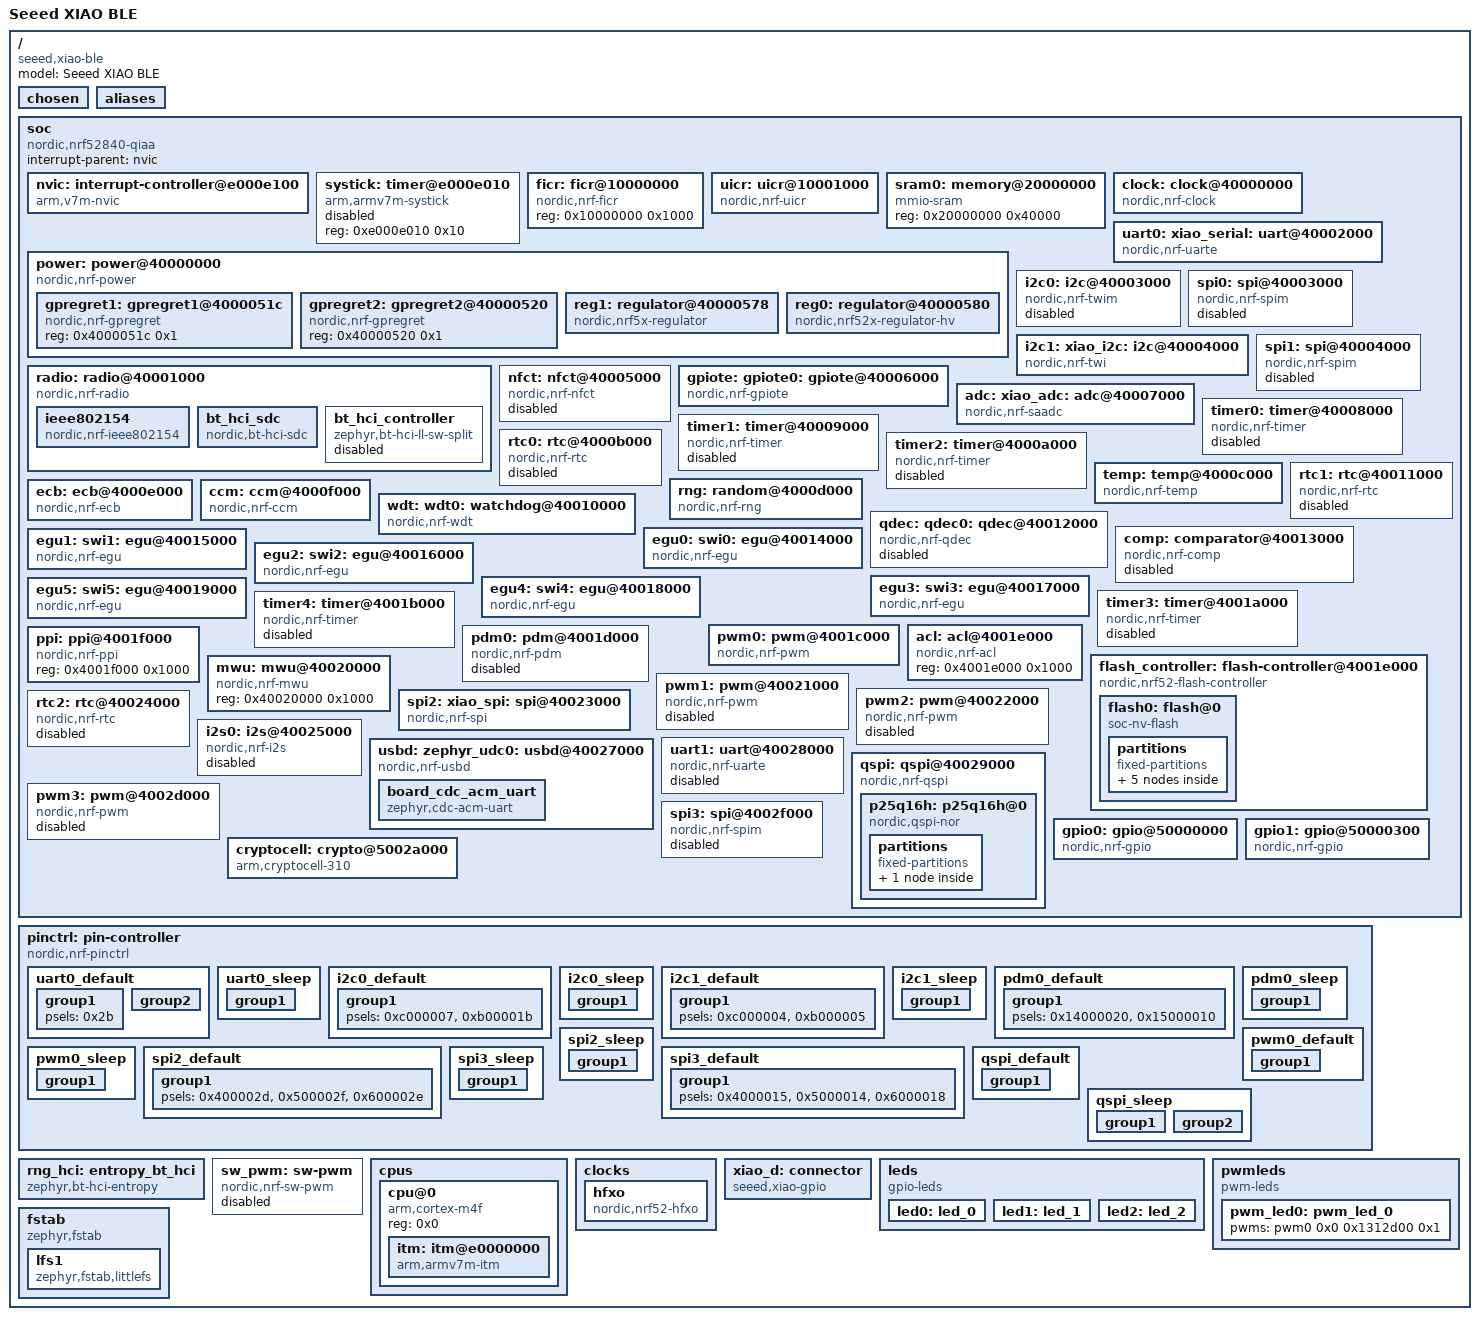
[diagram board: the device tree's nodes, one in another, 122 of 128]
/dts-v1/;

/* node '/' defined in zephyr\dts\common\skeleton.dtsi:9 */
/ {
	#address-cells = < 0x1 >;      /* in zephyr\dts\common\skeleton.dtsi:10 */
	#size-cells = < 0x1 >;         /* in zephyr\dts\common\skeleton.dtsi:11 */
	model = "Seeed XIAO BLE";      /* in zephyr\boards\seeed\xiao_ble\xiao_ble.dts:11 */
	compatible = "seeed,xiao-ble"; /* in zephyr\boards\seeed\xiao_ble\xiao_ble.dts:12 */

	/* node '/chosen' defined in zephyr\dts\common\skeleton.dtsi:12 */
	chosen {
		zephyr,bt-hci = &bt_hci_sdc;                 /* in zephyr\dts\arm\nordic\nrf52840.dtsi:10 */
		zephyr,entropy = &cryptocell;                /* in zephyr\dts\arm\nordic\nrf52840.dtsi:11 */
		zephyr,flash-controller = &flash_controller; /* in zephyr\dts\arm\nordic\nrf52840.dtsi:12 */
		zephyr,sram = &sram0;                        /* in zephyr\dts\vendor\nordic\nrf52840_partition_uf2_sdv7.dtsi:10 */
		zephyr,flash = &flash0;                      /* in zephyr\dts\vendor\nordic\nrf52840_partition_uf2_sdv7.dtsi:11 */
		zephyr,code-partition = &code_partition;     /* in zephyr\dts\vendor\nordic\nrf52840_partition_uf2_sdv7.dtsi:12 */
		zephyr,ieee802154 = &ieee802154;             /* in zephyr\boards\seeed\xiao_ble\xiao_ble_common.dtsi:15 */
		zephyr,console = &board_cdc_acm_uart;        /* in zephyr\boards\common\usb\cdc_acm_serial.dtsi:9 */
		zephyr,shell-uart = &board_cdc_acm_uart;     /* in zephyr\boards\common\usb\cdc_acm_serial.dtsi:10 */
		zephyr,uart-mcumgr = &board_cdc_acm_uart;    /* in zephyr\boards\common\usb\cdc_acm_serial.dtsi:11 */
		zephyr,bt-mon-uart = &board_cdc_acm_uart;    /* in zephyr\boards\common\usb\cdc_acm_serial.dtsi:12 */
		zephyr,bt-c2h-uart = &board_cdc_acm_uart;    /* in zephyr\boards\common\usb\cdc_acm_serial.dtsi:13 */
		nordic,pm-ext-flash = &p25q16h;              /* in pouch\examples\ble_gatt\app.overlay:7 */
	};

	/* node '/aliases' defined in zephyr\dts\common\skeleton.dtsi:13 */
	aliases {
		led0 = &led0;            /* in zephyr\boards\seeed\xiao_ble\xiao_ble_common.dtsi:43 */
		led1 = &led1;            /* in zephyr\boards\seeed\xiao_ble\xiao_ble_common.dtsi:44 */
		led2 = &led2;            /* in zephyr\boards\seeed\xiao_ble\xiao_ble_common.dtsi:45 */
		pwm-led0 = &pwm_led0;    /* in zephyr\boards\seeed\xiao_ble\xiao_ble_common.dtsi:46 */
		bootloader-led0 = &led0; /* in zephyr\boards\seeed\xiao_ble\xiao_ble_common.dtsi:47 */
		mcuboot-led0 = &led0;    /* in zephyr\boards\seeed\xiao_ble\xiao_ble_common.dtsi:48 */
		watchdog0 = &wdt0;       /* in zephyr\boards\seeed\xiao_ble\xiao_ble_common.dtsi:49 */
	};

	/* node '/soc' defined in zephyr\dts\arm\armv7-m.dtsi:6 */
	soc {
		#address-cells = < 0x1 >;            /* in zephyr\dts\arm\armv7-m.dtsi:7 */
		#size-cells = < 0x1 >;               /* in zephyr\dts\arm\armv7-m.dtsi:8 */
		compatible = "nordic,nrf52840-qiaa",
		             "nordic,nrf52840",
		             "nordic,nrf52",
		             "simple-bus";           /* in zephyr\dts\arm\nordic\nrf52840_qiaa.dtsi:29 */
		interrupt-parent = < &nvic >;        /* in zephyr\dts\arm\armv7-m.dtsi:10 */
		ranges;                              /* in zephyr\dts\arm\armv7-m.dtsi:11 */

		/* node '/soc/interrupt-controller@e000e100' defined in zephyr\dts\arm\armv7-m.dtsi:13 */
		nvic: interrupt-controller@e000e100 {
			#address-cells = < 0x1 >;            /* in zephyr\dts\arm\armv7-m.dtsi:14 */
			compatible = "arm,v7m-nvic";         /* in zephyr\dts\arm\armv7-m.dtsi:15 */
			reg = < 0xe000e100 0xc00 >;          /* in zephyr\dts\arm\armv7-m.dtsi:16 */
			interrupt-controller;                /* in zephyr\dts\arm\armv7-m.dtsi:17 */
			#interrupt-cells = < 0x2 >;          /* in zephyr\dts\arm\armv7-m.dtsi:18 */
			arm,num-irq-priority-bits = < 0x3 >; /* in zephyr\dts\arm\nordic\nrf52840.dtsi:582 */
			phandle = < 0x1 >;                   /* in zephyr\dts\arm\armv7-m.dtsi:10 */
		};

		/* node '/soc/timer@e000e010' defined in zephyr\dts\arm\armv7-m.dtsi:21 */
		systick: timer@e000e010 {
			compatible = "arm,armv7m-systick"; /* in zephyr\dts\arm\armv7-m.dtsi:22 */
			reg = < 0xe000e010 0x10 >;         /* in zephyr\dts\arm\armv7-m.dtsi:23 */
			status = "disabled";               /* in zephyr\dts\arm\nordic\nrf52840.dtsi:587 */
		};

		/* node '/soc/ficr@10000000' defined in zephyr\dts\arm\nordic\nrf52840.dtsi:44 */
		ficr: ficr@10000000 {
			compatible = "nordic,nrf-ficr"; /* in zephyr\dts\arm\nordic\nrf52840.dtsi:45 */
			reg = < 0x10000000 0x1000 >;    /* in zephyr\dts\arm\nordic\nrf52840.dtsi:46 */
			#nordic,ficr-cells = < 0x1 >;   /* in zephyr\dts\arm\nordic\nrf52840.dtsi:47 */
			status = "okay";                /* in zephyr\dts\arm\nordic\nrf52840.dtsi:48 */
		};

		/* node '/soc/uicr@10001000' defined in zephyr\dts\arm\nordic\nrf52840.dtsi:51 */
		uicr: uicr@10001000 {
			compatible = "nordic,nrf-uicr"; /* in zephyr\dts\arm\nordic\nrf52840.dtsi:52 */
			reg = < 0x10001000 0x1000 >;    /* in zephyr\dts\arm\nordic\nrf52840.dtsi:53 */
			status = "okay";                /* in zephyr\dts\arm\nordic\nrf52840.dtsi:54 */
			gpio-as-nreset;                 /* in zephyr\boards\seeed\xiao_ble\xiao_ble_common.dtsi:66 */
		};

		/* node '/soc/memory@20000000' defined in zephyr\dts\arm\nordic\nrf52840.dtsi:57 */
		sram0: memory@20000000 {
			compatible = "mmio-sram";     /* in zephyr\dts\arm\nordic\nrf52840.dtsi:58 */
			reg = < 0x20000000 0x40000 >; /* in zephyr\dts\arm\nordic\nrf52840_qiaa.dtsi:15 */
		};

		/* node '/soc/clock@40000000' defined in zephyr\dts\arm\nordic\nrf52840.dtsi:61 */
		clock: clock@40000000 {
			compatible = "nordic,nrf-clock"; /* in zephyr\dts\arm\nordic\nrf52840.dtsi:62 */
			reg = < 0x40000000 0x1000 >;     /* in zephyr\dts\arm\nordic\nrf52840.dtsi:63 */
			interrupts = < 0x0 0x1 >;        /* in zephyr\dts\arm\nordic\nrf52840.dtsi:64 */
			status = "okay";                 /* in zephyr\dts\arm\nordic\nrf52840.dtsi:65 */
		};

		/* node '/soc/power@40000000' defined in zephyr\dts\arm\nordic\nrf52840.dtsi:68 */
		power: power@40000000 {
			compatible = "nordic,nrf-power"; /* in zephyr\dts\arm\nordic\nrf52840.dtsi:69 */
			reg = < 0x40000000 0x1000 >;     /* in zephyr\dts\arm\nordic\nrf52840.dtsi:70 */
			interrupts = < 0x0 0x1 >;        /* in zephyr\dts\arm\nordic\nrf52840.dtsi:71 */
			status = "okay";                 /* in zephyr\dts\arm\nordic\nrf52840.dtsi:72 */
			#address-cells = < 0x1 >;        /* in zephyr\dts\arm\nordic\nrf52840.dtsi:73 */
			#size-cells = < 0x1 >;           /* in zephyr\dts\arm\nordic\nrf52840.dtsi:74 */

			/* node '/soc/power@40000000/gpregret1@4000051c' defined in zephyr\dts\arm\nordic\nrf52840.dtsi:76 */
			gpregret1: gpregret1@4000051c {
				#address-cells = < 0x1 >;           /* in zephyr\dts\arm\nordic\nrf52840.dtsi:77 */
				#size-cells = < 0x1 >;              /* in zephyr\dts\arm\nordic\nrf52840.dtsi:78 */
				compatible = "nordic,nrf-gpregret"; /* in zephyr\dts\arm\nordic\nrf52840.dtsi:79 */
				reg = < 0x4000051c 0x1 >;           /* in zephyr\dts\arm\nordic\nrf52840.dtsi:80 */
				status = "okay";                    /* in zephyr\dts\arm\nordic\nrf52840.dtsi:81 */
			};

			/* node '/soc/power@40000000/gpregret2@40000520' defined in zephyr\dts\arm\nordic\nrf52840.dtsi:84 */
			gpregret2: gpregret2@40000520 {
				#address-cells = < 0x1 >;           /* in zephyr\dts\arm\nordic\nrf52840.dtsi:85 */
				#size-cells = < 0x1 >;              /* in zephyr\dts\arm\nordic\nrf52840.dtsi:86 */
				compatible = "nordic,nrf-gpregret"; /* in zephyr\dts\arm\nordic\nrf52840.dtsi:87 */
				reg = < 0x40000520 0x1 >;           /* in zephyr\dts\arm\nordic\nrf52840.dtsi:88 */
				status = "okay";                    /* in zephyr\dts\arm\nordic\nrf52840.dtsi:89 */
			};

			/* node '/soc/power@40000000/regulator@40000578' defined in zephyr\dts\arm\nordic\nrf52840.dtsi:92 */
			reg1: regulator@40000578 {
				compatible = "nordic,nrf5x-regulator"; /* in zephyr\dts\arm\nordic\nrf52840.dtsi:93 */
				reg = < 0x40000578 0x1 >;              /* in zephyr\dts\arm\nordic\nrf52840.dtsi:94 */
				regulator-name = "REG1";               /* in zephyr\dts\arm\nordic\nrf52840.dtsi:95 */
				regulator-initial-mode = < 0x1 >;      /* in zephyr\boards\seeed\xiao_ble\xiao_ble_common.dtsi:58 */
			};

			/* node '/soc/power@40000000/regulator@40000580' defined in zephyr\dts\arm\nordic\nrf52840_qiaa.dtsi:19 */
			reg0: regulator@40000580 {
				compatible = "nordic,nrf52x-regulator-hv"; /* in zephyr\dts\arm\nordic\nrf52840_qiaa.dtsi:20 */
				reg = < 0x40000580 0x1 >;                  /* in zephyr\dts\arm\nordic\nrf52840_qiaa.dtsi:21 */
				regulator-name = "REG0";                   /* in zephyr\dts\arm\nordic\nrf52840_qiaa.dtsi:22 */
				status = "okay";                           /* in zephyr\boards\seeed\xiao_ble\xiao_ble_common.dtsi:54 */
			};
		};

		/* node '/soc/radio@40001000' defined in zephyr\dts\arm\nordic\nrf52840.dtsi:100 */
		radio: radio@40001000 {
			compatible = "nordic,nrf-radio"; /* in zephyr\dts\arm\nordic\nrf52840.dtsi:101 */
			reg = < 0x40001000 0x1000 >;     /* in zephyr\dts\arm\nordic\nrf52840.dtsi:102 */
			interrupts = < 0x1 0x1 >;        /* in zephyr\dts\arm\nordic\nrf52840.dtsi:103 */
			status = "okay";                 /* in zephyr\dts\arm\nordic\nrf52840.dtsi:104 */
			ieee802154-supported;            /* in zephyr\dts\arm\nordic\nrf52840.dtsi:105 */
			ble-2mbps-supported;             /* in zephyr\dts\arm\nordic\nrf52840.dtsi:106 */
			ble-coded-phy-supported;         /* in zephyr\dts\arm\nordic\nrf52840.dtsi:107 */
			tx-high-power-supported;         /* in zephyr\dts\arm\nordic\nrf52840.dtsi:108 */

			/* node '/soc/radio@40001000/ieee802154' defined in zephyr\dts\arm\nordic\nrf52840.dtsi:110 */
			ieee802154: ieee802154 {
				compatible = "nordic,nrf-ieee802154"; /* in zephyr\dts\arm\nordic\nrf52840.dtsi:111 */
				status = "okay";                      /* in zephyr\boards\seeed\xiao_ble\xiao_ble_common.dtsi:138 */
			};

			/* node '/soc/radio@40001000/bt_hci_sdc' defined in zephyr\dts\arm\nordic\nrf52840.dtsi:115 */
			bt_hci_sdc: bt_hci_sdc {
				compatible = "nordic,bt-hci-sdc"; /* in zephyr\dts\arm\nordic\nrf52840.dtsi:116 */
				status = "okay";                  /* in zephyr\dts\arm\nordic\nrf52840.dtsi:117 */
			};

			/* node '/soc/radio@40001000/bt_hci_controller' defined in zephyr\dts\arm\nordic\nrf52840.dtsi:119 */
			bt_hci_controller: bt_hci_controller {
				compatible = "zephyr,bt-hci-ll-sw-split"; /* in zephyr\dts\arm\nordic\nrf52840.dtsi:120 */
				status = "disabled";                      /* in zephyr\dts\arm\nordic\nrf52840.dtsi:121 */
			};
		};

		/* node '/soc/uart@40002000' defined in zephyr\dts\arm\nordic\nrf52840.dtsi:125 */
		uart0: xiao_serial: uart@40002000 {
			compatible = "nordic,nrf-uarte"; /* in zephyr\boards\seeed\xiao_ble\xiao_ble_common.dtsi:82 */
			reg = < 0x40002000 0x1000 >;     /* in zephyr\dts\arm\nordic\nrf52840.dtsi:129 */
			interrupts = < 0x2 0x1 >;        /* in zephyr\dts\arm\nordic\nrf52840.dtsi:130 */
			status = "okay";                 /* in zephyr\boards\seeed\xiao_ble\xiao_ble_common.dtsi:83 */
			current-speed = < 0x1c200 >;     /* in zephyr\boards\seeed\xiao_ble\xiao_ble_common.dtsi:84 */
			pinctrl-0 = < &uart0_default >;  /* in zephyr\boards\seeed\xiao_ble\xiao_ble_common.dtsi:85 */
			pinctrl-1 = < &uart0_sleep >;    /* in zephyr\boards\seeed\xiao_ble\xiao_ble_common.dtsi:86 */
			pinctrl-names = "default",
			                "sleep";         /* in zephyr\boards\seeed\xiao_ble\xiao_ble_common.dtsi:87 */
		};

		/* node '/soc/i2c@40003000' defined in zephyr\dts\arm\nordic\nrf52840.dtsi:134 */
		i2c0: i2c@40003000 {
			compatible = "nordic,nrf-twim"; /* in zephyr\dts\arm\nordic\nrf52840.dtsi:142 */
			#address-cells = < 0x1 >;       /* in zephyr\dts\arm\nordic\nrf52840.dtsi:143 */
			#size-cells = < 0x0 >;          /* in zephyr\dts\arm\nordic\nrf52840.dtsi:144 */
			reg = < 0x40003000 0x1000 >;    /* in zephyr\dts\arm\nordic\nrf52840.dtsi:145 */
			interrupts = < 0x3 0x1 >;       /* in zephyr\dts\arm\nordic\nrf52840.dtsi:146 */
			easydma-maxcnt-bits = < 0x10 >; /* in zephyr\dts\arm\nordic\nrf52840.dtsi:147 */
			status = "disabled";            /* in zephyr\dts\arm\nordic\nrf52840.dtsi:148 */
			zephyr,pm-device-runtime-auto;  /* in zephyr\dts\arm\nordic\nrf52840.dtsi:149 */
		};

		/* node '/soc/spi@40003000' defined in zephyr\dts\arm\nordic\nrf52840.dtsi:152 */
		spi0: spi@40003000 {
			compatible = "nordic,nrf-spim"; /* in zephyr\dts\arm\nordic\nrf52840.dtsi:160 */
			#address-cells = < 0x1 >;       /* in zephyr\dts\arm\nordic\nrf52840.dtsi:161 */
			#size-cells = < 0x0 >;          /* in zephyr\dts\arm\nordic\nrf52840.dtsi:162 */
			reg = < 0x40003000 0x1000 >;    /* in zephyr\dts\arm\nordic\nrf52840.dtsi:163 */
			interrupts = < 0x3 0x1 >;       /* in zephyr\dts\arm\nordic\nrf52840.dtsi:164 */
			max-frequency = < 0x7a1200 >;   /* in zephyr\dts\arm\nordic\nrf52840.dtsi:165 */
			easydma-maxcnt-bits = < 0x10 >; /* in zephyr\dts\arm\nordic\nrf52840.dtsi:166 */
			status = "disabled";            /* in zephyr\dts\arm\nordic\nrf52840.dtsi:167 */
		};

		/* node '/soc/i2c@40004000' defined in zephyr\dts\arm\nordic\nrf52840.dtsi:170 */
		i2c1: xiao_i2c: i2c@40004000 {
			compatible = "nordic,nrf-twi";  /* in zephyr\boards\seeed\xiao_ble\xiao_ble_common.dtsi:91 */
			#address-cells = < 0x1 >;       /* in zephyr\dts\arm\nordic\nrf52840.dtsi:179 */
			#size-cells = < 0x0 >;          /* in zephyr\dts\arm\nordic\nrf52840.dtsi:180 */
			reg = < 0x40004000 0x1000 >;    /* in zephyr\dts\arm\nordic\nrf52840.dtsi:181 */
			interrupts = < 0x4 0x1 >;       /* in zephyr\dts\arm\nordic\nrf52840.dtsi:182 */
			easydma-maxcnt-bits = < 0x10 >; /* in zephyr\dts\arm\nordic\nrf52840.dtsi:183 */
			status = "okay";                /* in zephyr\boards\seeed\xiao_ble\xiao_ble_common.dtsi:93 */
			zephyr,pm-device-runtime-auto;  /* in zephyr\dts\arm\nordic\nrf52840.dtsi:185 */
			pinctrl-0 = < &i2c1_default >;  /* in zephyr\boards\seeed\xiao_ble\xiao_ble_common.dtsi:94 */
			pinctrl-1 = < &i2c1_sleep >;    /* in zephyr\boards\seeed\xiao_ble\xiao_ble_common.dtsi:95 */
			pinctrl-names = "default",
			                "sleep";        /* in zephyr\boards\seeed\xiao_ble\xiao_ble_common.dtsi:96 */
		};

		/* node '/soc/spi@40004000' defined in zephyr\dts\arm\nordic\nrf52840.dtsi:188 */
		spi1: spi@40004000 {
			compatible = "nordic,nrf-spim"; /* in zephyr\dts\arm\nordic\nrf52840.dtsi:196 */
			#address-cells = < 0x1 >;       /* in zephyr\dts\arm\nordic\nrf52840.dtsi:197 */
			#size-cells = < 0x0 >;          /* in zephyr\dts\arm\nordic\nrf52840.dtsi:198 */
			reg = < 0x40004000 0x1000 >;    /* in zephyr\dts\arm\nordic\nrf52840.dtsi:199 */
			interrupts = < 0x4 0x1 >;       /* in zephyr\dts\arm\nordic\nrf52840.dtsi:200 */
			max-frequency = < 0x7a1200 >;   /* in zephyr\dts\arm\nordic\nrf52840.dtsi:201 */
			easydma-maxcnt-bits = < 0x10 >; /* in zephyr\dts\arm\nordic\nrf52840.dtsi:202 */
			status = "disabled";            /* in zephyr\dts\arm\nordic\nrf52840.dtsi:203 */
		};

		/* node '/soc/nfct@40005000' defined in zephyr\dts\arm\nordic\nrf52840.dtsi:206 */
		nfct: nfct@40005000 {
			compatible = "nordic,nrf-nfct"; /* in zephyr\dts\arm\nordic\nrf52840.dtsi:207 */
			reg = < 0x40005000 0x1000 >;    /* in zephyr\dts\arm\nordic\nrf52840.dtsi:208 */
			interrupts = < 0x5 0x1 >;       /* in zephyr\dts\arm\nordic\nrf52840.dtsi:209 */
			status = "disabled";            /* in zephyr\dts\arm\nordic\nrf52840.dtsi:210 */
		};

		/* node '/soc/gpiote@40006000' defined in zephyr\dts\arm\nordic\nrf52840.dtsi:213 */
		gpiote: gpiote0: gpiote@40006000 {
			compatible = "nordic,nrf-gpiote"; /* in zephyr\dts\arm\nordic\nrf52840.dtsi:214 */
			reg = < 0x40006000 0x1000 >;      /* in zephyr\dts\arm\nordic\nrf52840.dtsi:215 */
			interrupts = < 0x6 0x5 >;         /* in zephyr\dts\arm\nordic\nrf52840.dtsi:216 */
			status = "okay";                  /* in zephyr\boards\seeed\xiao_ble\xiao_ble_common.dtsi:70 */
			instance = < 0x0 >;               /* in zephyr\dts\arm\nordic\nrf52840.dtsi:218 */
			phandle = < 0xc >;                /* in zephyr\dts\arm\nordic\nrf52840.dtsi:556 */
		};

		/* node '/soc/adc@40007000' defined in zephyr\dts\arm\nordic\nrf52840.dtsi:221 */
		adc: xiao_adc: adc@40007000 {
			compatible = "nordic,nrf-saadc"; /* in zephyr\dts\arm\nordic\nrf52840.dtsi:222 */
			reg = < 0x40007000 0x1000 >;     /* in zephyr\dts\arm\nordic\nrf52840.dtsi:223 */
			interrupts = < 0x7 0x1 >;        /* in zephyr\dts\arm\nordic\nrf52840.dtsi:224 */
			status = "okay";                 /* in zephyr\boards\seeed\xiao_ble\xiao_ble_common.dtsi:62 */
			#io-channel-cells = < 0x1 >;     /* in zephyr\dts\arm\nordic\nrf52840.dtsi:226 */
			zephyr,pm-device-runtime-auto;   /* in zephyr\dts\arm\nordic\nrf52840.dtsi:227 */
		};

		/* node '/soc/timer@40008000' defined in zephyr\dts\arm\nordic\nrf52840.dtsi:230 */
		timer0: timer@40008000 {
			compatible = "nordic,nrf-timer"; /* in zephyr\dts\arm\nordic\nrf52840.dtsi:231 */
			status = "disabled";             /* in zephyr\dts\arm\nordic\nrf52840.dtsi:232 */
			reg = < 0x40008000 0x1000 >;     /* in zephyr\dts\arm\nordic\nrf52840.dtsi:233 */
			cc-num = < 0x4 >;                /* in zephyr\dts\arm\nordic\nrf52840.dtsi:234 */
			max-bit-width = < 0x20 >;        /* in zephyr\dts\arm\nordic\nrf52840.dtsi:235 */
			interrupts = < 0x8 0x1 >;        /* in zephyr\dts\arm\nordic\nrf52840.dtsi:236 */
			prescaler = < 0x0 >;             /* in zephyr\dts\arm\nordic\nrf52840.dtsi:237 */
		};

		/* node '/soc/timer@40009000' defined in zephyr\dts\arm\nordic\nrf52840.dtsi:240 */
		timer1: timer@40009000 {
			compatible = "nordic,nrf-timer"; /* in zephyr\dts\arm\nordic\nrf52840.dtsi:241 */
			status = "disabled";             /* in zephyr\dts\arm\nordic\nrf52840.dtsi:242 */
			reg = < 0x40009000 0x1000 >;     /* in zephyr\dts\arm\nordic\nrf52840.dtsi:243 */
			cc-num = < 0x4 >;                /* in zephyr\dts\arm\nordic\nrf52840.dtsi:244 */
			max-bit-width = < 0x20 >;        /* in zephyr\dts\arm\nordic\nrf52840.dtsi:245 */
			interrupts = < 0x9 0x1 >;        /* in zephyr\dts\arm\nordic\nrf52840.dtsi:246 */
			prescaler = < 0x0 >;             /* in zephyr\dts\arm\nordic\nrf52840.dtsi:247 */
			phandle = < 0xd >;               /* in zephyr\dts\vendor\nordic\nrf_common.dtsi:41 */
		};

		/* node '/soc/timer@4000a000' defined in zephyr\dts\arm\nordic\nrf52840.dtsi:250 */
		timer2: timer@4000a000 {
			compatible = "nordic,nrf-timer"; /* in zephyr\dts\arm\nordic\nrf52840.dtsi:251 */
			status = "disabled";             /* in zephyr\dts\arm\nordic\nrf52840.dtsi:252 */
			reg = < 0x4000a000 0x1000 >;     /* in zephyr\dts\arm\nordic\nrf52840.dtsi:253 */
			cc-num = < 0x4 >;                /* in zephyr\dts\arm\nordic\nrf52840.dtsi:254 */
			max-bit-width = < 0x20 >;        /* in zephyr\dts\arm\nordic\nrf52840.dtsi:255 */
			interrupts = < 0xa 0x1 >;        /* in zephyr\dts\arm\nordic\nrf52840.dtsi:256 */
			prescaler = < 0x0 >;             /* in zephyr\dts\arm\nordic\nrf52840.dtsi:257 */
		};

		/* node '/soc/rtc@4000b000' defined in zephyr\dts\arm\nordic\nrf52840.dtsi:260 */
		rtc0: rtc@4000b000 {
			compatible = "nordic,nrf-rtc"; /* in zephyr\dts\arm\nordic\nrf52840.dtsi:261 */
			reg = < 0x4000b000 0x1000 >;   /* in zephyr\dts\arm\nordic\nrf52840.dtsi:262 */
			cc-num = < 0x3 >;              /* in zephyr\dts\arm\nordic\nrf52840.dtsi:263 */
			interrupts = < 0xb 0x1 >;      /* in zephyr\dts\arm\nordic\nrf52840.dtsi:264 */
			status = "disabled";           /* in zephyr\dts\arm\nordic\nrf52840.dtsi:265 */
			clock-frequency = < 0x8000 >;  /* in zephyr\dts\arm\nordic\nrf52840.dtsi:266 */
			prescaler = < 0x1 >;           /* in zephyr\dts\arm\nordic\nrf52840.dtsi:267 */
		};

		/* node '/soc/temp@4000c000' defined in zephyr\dts\arm\nordic\nrf52840.dtsi:270 */
		temp: temp@4000c000 {
			compatible = "nordic,nrf-temp"; /* in zephyr\dts\arm\nordic\nrf52840.dtsi:271 */
			reg = < 0x4000c000 0x1000 >;    /* in zephyr\dts\arm\nordic\nrf52840.dtsi:272 */
			interrupts = < 0xc 0x1 >;       /* in zephyr\dts\arm\nordic\nrf52840.dtsi:273 */
			status = "okay";                /* in zephyr\dts\arm\nordic\nrf52840.dtsi:274 */
		};

		/* node '/soc/random@4000d000' defined in zephyr\dts\arm\nordic\nrf52840.dtsi:277 */
		rng: random@4000d000 {
			compatible = "nordic,nrf-rng"; /* in zephyr\dts\arm\nordic\nrf52840.dtsi:278 */
			reg = < 0x4000d000 0x1000 >;   /* in zephyr\dts\arm\nordic\nrf52840.dtsi:279 */
			interrupts = < 0xd 0x1 >;      /* in zephyr\dts\arm\nordic\nrf52840.dtsi:280 */
			status = "okay";               /* in zephyr\dts\arm\nordic\nrf52840.dtsi:281 */
		};

		/* node '/soc/ecb@4000e000' defined in zephyr\dts\arm\nordic\nrf52840.dtsi:284 */
		ecb: ecb@4000e000 {
			compatible = "nordic,nrf-ecb"; /* in zephyr\dts\arm\nordic\nrf52840.dtsi:285 */
			reg = < 0x4000e000 0x1000 >;   /* in zephyr\dts\arm\nordic\nrf52840.dtsi:286 */
			interrupts = < 0xe 0x1 >;      /* in zephyr\dts\arm\nordic\nrf52840.dtsi:287 */
			status = "okay";               /* in zephyr\dts\arm\nordic\nrf52840.dtsi:288 */
		};

		/* node '/soc/ccm@4000f000' defined in zephyr\dts\arm\nordic\nrf52840.dtsi:291 */
		ccm: ccm@4000f000 {
			compatible = "nordic,nrf-ccm"; /* in zephyr\dts\arm\nordic\nrf52840.dtsi:292 */
			reg = < 0x4000f000 0x1000 >;   /* in zephyr\dts\arm\nordic\nrf52840.dtsi:293 */
			interrupts = < 0xf 0x1 >;      /* in zephyr\dts\arm\nordic\nrf52840.dtsi:294 */
			length-field-length-8-bits;    /* in zephyr\dts\arm\nordic\nrf52840.dtsi:295 */
			status = "okay";               /* in zephyr\dts\arm\nordic\nrf52840.dtsi:296 */
		};

		/* node '/soc/watchdog@40010000' defined in zephyr\dts\arm\nordic\nrf52840.dtsi:299 */
		wdt: wdt0: watchdog@40010000 {
			compatible = "nordic,nrf-wdt"; /* in zephyr\dts\arm\nordic\nrf52840.dtsi:300 */
			reg = < 0x40010000 0x1000 >;   /* in zephyr\dts\arm\nordic\nrf52840.dtsi:301 */
			interrupts = < 0x10 0x1 >;     /* in zephyr\dts\arm\nordic\nrf52840.dtsi:302 */
			status = "okay";               /* in zephyr\dts\arm\nordic\nrf52840.dtsi:303 */
		};

		/* node '/soc/rtc@40011000' defined in zephyr\dts\arm\nordic\nrf52840.dtsi:306 */
		rtc1: rtc@40011000 {
			compatible = "nordic,nrf-rtc"; /* in zephyr\dts\arm\nordic\nrf52840.dtsi:307 */
			reg = < 0x40011000 0x1000 >;   /* in zephyr\dts\arm\nordic\nrf52840.dtsi:308 */
			cc-num = < 0x4 >;              /* in zephyr\dts\arm\nordic\nrf52840.dtsi:309 */
			interrupts = < 0x11 0x1 >;     /* in zephyr\dts\arm\nordic\nrf52840.dtsi:310 */
			status = "disabled";           /* in zephyr\dts\arm\nordic\nrf52840.dtsi:311 */
			clock-frequency = < 0x8000 >;  /* in zephyr\dts\arm\nordic\nrf52840.dtsi:312 */
			prescaler = < 0x1 >;           /* in zephyr\dts\arm\nordic\nrf52840.dtsi:313 */
		};

		/* node '/soc/qdec@40012000' defined in zephyr\dts\arm\nordic\nrf52840.dtsi:316 */
		qdec: qdec0: qdec@40012000 {
			compatible = "nordic,nrf-qdec"; /* in zephyr\dts\arm\nordic\nrf52840.dtsi:317 */
			reg = < 0x40012000 0x1000 >;    /* in zephyr\dts\arm\nordic\nrf52840.dtsi:318 */
			interrupts = < 0x12 0x1 >;      /* in zephyr\dts\arm\nordic\nrf52840.dtsi:319 */
			status = "disabled";            /* in zephyr\dts\arm\nordic\nrf52840.dtsi:320 */
		};

		/* node '/soc/comparator@40013000' defined in zephyr\dts\arm\nordic\nrf52840.dtsi:323 */
		comp: comparator@40013000 {
			compatible = "nordic,nrf-comp"; /* in zephyr\dts\arm\nordic\nrf52840.dtsi:328 */
			reg = < 0x40013000 0x1000 >;    /* in zephyr\dts\arm\nordic\nrf52840.dtsi:329 */
			interrupts = < 0x13 0x1 >;      /* in zephyr\dts\arm\nordic\nrf52840.dtsi:330 */
			status = "disabled";            /* in zephyr\dts\arm\nordic\nrf52840.dtsi:331 */
		};

		/* node '/soc/egu@40014000' defined in zephyr\dts\arm\nordic\nrf52840.dtsi:334 */
		egu0: swi0: egu@40014000 {
			compatible = "nordic,nrf-egu",
			             "nordic,nrf-swi"; /* in zephyr\dts\arm\nordic\nrf52840.dtsi:335 */
			reg = < 0x40014000 0x1000 >;   /* in zephyr\dts\arm\nordic\nrf52840.dtsi:336 */
			interrupts = < 0x14 0x1 >;     /* in zephyr\dts\arm\nordic\nrf52840.dtsi:337 */
			status = "okay";               /* in zephyr\dts\arm\nordic\nrf52840.dtsi:338 */
		};

		/* node '/soc/egu@40015000' defined in zephyr\dts\arm\nordic\nrf52840.dtsi:341 */
		egu1: swi1: egu@40015000 {
			compatible = "nordic,nrf-egu",
			             "nordic,nrf-swi"; /* in zephyr\dts\arm\nordic\nrf52840.dtsi:342 */
			reg = < 0x40015000 0x1000 >;   /* in zephyr\dts\arm\nordic\nrf52840.dtsi:343 */
			interrupts = < 0x15 0x1 >;     /* in zephyr\dts\arm\nordic\nrf52840.dtsi:344 */
			status = "okay";               /* in zephyr\dts\arm\nordic\nrf52840.dtsi:345 */
		};

		/* node '/soc/egu@40016000' defined in zephyr\dts\arm\nordic\nrf52840.dtsi:348 */
		egu2: swi2: egu@40016000 {
			compatible = "nordic,nrf-egu",
			             "nordic,nrf-swi"; /* in zephyr\dts\arm\nordic\nrf52840.dtsi:349 */
			reg = < 0x40016000 0x1000 >;   /* in zephyr\dts\arm\nordic\nrf52840.dtsi:350 */
			interrupts = < 0x16 0x1 >;     /* in zephyr\dts\arm\nordic\nrf52840.dtsi:351 */
			status = "okay";               /* in zephyr\dts\arm\nordic\nrf52840.dtsi:352 */
		};

		/* node '/soc/egu@40017000' defined in zephyr\dts\arm\nordic\nrf52840.dtsi:355 */
		egu3: swi3: egu@40017000 {
			compatible = "nordic,nrf-egu",
			             "nordic,nrf-swi"; /* in zephyr\dts\arm\nordic\nrf52840.dtsi:356 */
			reg = < 0x40017000 0x1000 >;   /* in zephyr\dts\arm\nordic\nrf52840.dtsi:357 */
			interrupts = < 0x17 0x1 >;     /* in zephyr\dts\arm\nordic\nrf52840.dtsi:358 */
			status = "okay";               /* in zephyr\dts\arm\nordic\nrf52840.dtsi:359 */
		};

		/* node '/soc/egu@40018000' defined in zephyr\dts\arm\nordic\nrf52840.dtsi:362 */
		egu4: swi4: egu@40018000 {
			compatible = "nordic,nrf-egu",
			             "nordic,nrf-swi"; /* in zephyr\dts\arm\nordic\nrf52840.dtsi:363 */
			reg = < 0x40018000 0x1000 >;   /* in zephyr\dts\arm\nordic\nrf52840.dtsi:364 */
			interrupts = < 0x18 0x1 >;     /* in zephyr\dts\arm\nordic\nrf52840.dtsi:365 */
			status = "okay";               /* in zephyr\dts\arm\nordic\nrf52840.dtsi:366 */
		};

		/* node '/soc/egu@40019000' defined in zephyr\dts\arm\nordic\nrf52840.dtsi:369 */
		egu5: swi5: egu@40019000 {
			compatible = "nordic,nrf-egu",
			             "nordic,nrf-swi"; /* in zephyr\dts\arm\nordic\nrf52840.dtsi:370 */
			reg = < 0x40019000 0x1000 >;   /* in zephyr\dts\arm\nordic\nrf52840.dtsi:371 */
			interrupts = < 0x19 0x1 >;     /* in zephyr\dts\arm\nordic\nrf52840.dtsi:372 */
			status = "okay";               /* in zephyr\dts\arm\nordic\nrf52840.dtsi:373 */
		};

		/* node '/soc/timer@4001a000' defined in zephyr\dts\arm\nordic\nrf52840.dtsi:376 */
		timer3: timer@4001a000 {
			compatible = "nordic,nrf-timer"; /* in zephyr\dts\arm\nordic\nrf52840.dtsi:377 */
			status = "disabled";             /* in zephyr\dts\arm\nordic\nrf52840.dtsi:378 */
			reg = < 0x4001a000 0x1000 >;     /* in zephyr\dts\arm\nordic\nrf52840.dtsi:379 */
			cc-num = < 0x6 >;                /* in zephyr\dts\arm\nordic\nrf52840.dtsi:380 */
			max-bit-width = < 0x20 >;        /* in zephyr\dts\arm\nordic\nrf52840.dtsi:381 */
			interrupts = < 0x1a 0x1 >;       /* in zephyr\dts\arm\nordic\nrf52840.dtsi:382 */
			prescaler = < 0x0 >;             /* in zephyr\dts\arm\nordic\nrf52840.dtsi:383 */
		};

		/* node '/soc/timer@4001b000' defined in zephyr\dts\arm\nordic\nrf52840.dtsi:386 */
		timer4: timer@4001b000 {
			compatible = "nordic,nrf-timer"; /* in zephyr\dts\arm\nordic\nrf52840.dtsi:387 */
			status = "disabled";             /* in zephyr\dts\arm\nordic\nrf52840.dtsi:388 */
			reg = < 0x4001b000 0x1000 >;     /* in zephyr\dts\arm\nordic\nrf52840.dtsi:389 */
			cc-num = < 0x6 >;                /* in zephyr\dts\arm\nordic\nrf52840.dtsi:390 */
			max-bit-width = < 0x20 >;        /* in zephyr\dts\arm\nordic\nrf52840.dtsi:391 */
			interrupts = < 0x1b 0x1 >;       /* in zephyr\dts\arm\nordic\nrf52840.dtsi:392 */
			prescaler = < 0x0 >;             /* in zephyr\dts\arm\nordic\nrf52840.dtsi:393 */
		};

		/* node '/soc/pwm@4001c000' defined in zephyr\dts\arm\nordic\nrf52840.dtsi:396 */
		pwm0: pwm@4001c000 {
			compatible = "nordic,nrf-pwm"; /* in zephyr\dts\arm\nordic\nrf52840.dtsi:397 */
			reg = < 0x4001c000 0x1000 >;   /* in zephyr\dts\arm\nordic\nrf52840.dtsi:398 */
			interrupts = < 0x1c 0x1 >;     /* in zephyr\dts\arm\nordic\nrf52840.dtsi:399 */
			status = "okay";               /* in zephyr\boards\seeed\xiao_ble\xiao_ble_common.dtsi:100 */
			#pwm-cells = < 0x3 >;          /* in zephyr\dts\arm\nordic\nrf52840.dtsi:401 */
			pinctrl-0 = < &pwm0_default >; /* in zephyr\boards\seeed\xiao_ble\xiao_ble_common.dtsi:101 */
			pinctrl-1 = < &pwm0_sleep >;   /* in zephyr\boards\seeed\xiao_ble\xiao_ble_common.dtsi:102 */
			pinctrl-names = "default",
			                "sleep";       /* in zephyr\boards\seeed\xiao_ble\xiao_ble_common.dtsi:103 */
			phandle = < 0x10 >;            /* in zephyr\boards\seeed\xiao_ble\xiao_ble_common.dtsi:37 */
		};

		/* node '/soc/pdm@4001d000' defined in zephyr\dts\arm\nordic\nrf52840.dtsi:404 */
		pdm0: pdm@4001d000 {
			compatible = "nordic,nrf-pdm"; /* in zephyr\dts\arm\nordic\nrf52840.dtsi:405 */
			reg = < 0x4001d000 0x1000 >;   /* in zephyr\dts\arm\nordic\nrf52840.dtsi:406 */
			interrupts = < 0x1d 0x1 >;     /* in zephyr\dts\arm\nordic\nrf52840.dtsi:407 */
			status = "disabled";           /* in zephyr\dts\arm\nordic\nrf52840.dtsi:408 */
		};

		/* node '/soc/acl@4001e000' defined in zephyr\dts\arm\nordic\nrf52840.dtsi:411 */
		acl: acl@4001e000 {
			compatible = "nordic,nrf-acl"; /* in zephyr\dts\arm\nordic\nrf52840.dtsi:412 */
			reg = < 0x4001e000 0x1000 >;   /* in zephyr\dts\arm\nordic\nrf52840.dtsi:413 */
			status = "okay";               /* in zephyr\dts\arm\nordic\nrf52840.dtsi:414 */
		};

		/* node '/soc/flash-controller@4001e000' defined in zephyr\dts\arm\nordic\nrf52840.dtsi:417 */
		flash_controller: flash-controller@4001e000 {
			compatible = "nordic,nrf52-flash-controller"; /* in zephyr\dts\arm\nordic\nrf52840.dtsi:418 */
			reg = < 0x4001e000 0x1000 >;                  /* in zephyr\dts\arm\nordic\nrf52840.dtsi:419 */
			partial-erase;                                /* in zephyr\dts\arm\nordic\nrf52840.dtsi:420 */
			#address-cells = < 0x1 >;                     /* in zephyr\dts\arm\nordic\nrf52840.dtsi:422 */
			#size-cells = < 0x1 >;                        /* in zephyr\dts\arm\nordic\nrf52840.dtsi:423 */

			/* node '/soc/flash-controller@4001e000/flash@0' defined in zephyr\dts\arm\nordic\nrf52840.dtsi:426 */
			flash0: flash@0 {
				compatible = "soc-nv-flash";   /* in zephyr\dts\arm\nordic\nrf52840.dtsi:427 */
				erase-block-size = < 0x1000 >; /* in zephyr\dts\arm\nordic\nrf52840.dtsi:428 */
				write-block-size = < 0x4 >;    /* in zephyr\dts\arm\nordic\nrf52840.dtsi:429 */
				reg = < 0x0 0x100000 >;        /* in zephyr\dts\arm\nordic\nrf52840_qiaa.dtsi:11 */

				/* node '/soc/flash-controller@4001e000/flash@0/partitions' defined in zephyr\dts\vendor\nordic\nrf52840_partition_uf2_sdv7.dtsi:26 */
				partitions {
					compatible = "fixed-partitions"; /* in zephyr\dts\vendor\nordic\nrf52840_partition_uf2_sdv7.dtsi:27 */
					#address-cells = < 0x1 >;        /* in zephyr\dts\vendor\nordic\nrf52840_partition_uf2_sdv7.dtsi:28 */
					#size-cells = < 0x1 >;           /* in zephyr\dts\vendor\nordic\nrf52840_partition_uf2_sdv7.dtsi:29 */

					/* node '/soc/flash-controller@4001e000/flash@0/partitions/partition@0' defined in zephyr\dts\vendor\nordic\nrf52840_partition_uf2_sdv7.dtsi:31 */
					reserved_partition_0: partition@0 {
						label = "SoftDevice";  /* in zephyr\dts\vendor\nordic\nrf52840_partition_uf2_sdv7.dtsi:32 */
						read-only;             /* in zephyr\dts\vendor\nordic\nrf52840_partition_uf2_sdv7.dtsi:33 */
						reg = < 0x0 0x27000 >; /* in zephyr\dts\vendor\nordic\nrf52840_partition_uf2_sdv7.dtsi:34 */
					};

					/* node '/soc/flash-controller@4001e000/flash@0/partitions/partition@27000' defined in zephyr\dts\vendor\nordic\nrf52840_partition_uf2_sdv7.dtsi:37 */
					code_partition: partition@27000 {
						label = "Application";     /* in zephyr\dts\vendor\nordic\nrf52840_partition_uf2_sdv7.dtsi:38 */
						reg = < 0x27000 0xc5000 >; /* in zephyr\dts\vendor\nordic\nrf52840_partition_uf2_sdv7.dtsi:39 */
					};

					/* node '/soc/flash-controller@4001e000/flash@0/partitions/partition@ec000' defined in zephyr\dts\vendor\nordic\nrf52840_partition_uf2_sdv7.dtsi:42 */
					storage_partition: partition@ec000 {
						label = "Storage";        /* in zephyr\dts\vendor\nordic\nrf52840_partition_uf2_sdv7.dtsi:43 */
						reg = < 0xec000 0x8000 >; /* in zephyr\dts\vendor\nordic\nrf52840_partition_uf2_sdv7.dtsi:44 */
						phandle = < 0x11 >;       /* in pouch\examples\ble_gatt\app.overlay:15 */
					};

					/* node '/soc/flash-controller@4001e000/flash@0/partitions/partition@f4000' defined in zephyr\dts\vendor\nordic\nrf52840_partition_uf2_sdv7.dtsi:47 */
					boot_partition: partition@f4000 {
						label = "UF2";            /* in zephyr\dts\vendor\nordic\nrf52840_partition_uf2_sdv7.dtsi:48 */
						read-only;                /* in zephyr\dts\vendor\nordic\nrf52840_partition_uf2_sdv7.dtsi:49 */
						reg = < 0xf4000 0xc000 >; /* in zephyr\dts\vendor\nordic\nrf52840_partition_uf2_sdv7.dtsi:50 */
					};

					/* node '/soc/flash-controller@4001e000/flash@0/partitions/partition@e000' defined in pouch\examples\ble_gatt\app.overlay:28 */
					slot0_partition: partition@e000 {
						label = "slot0";          /* in pouch\examples\ble_gatt\app.overlay:29 */
						reg = < 0xe000 0x61000 >; /* in pouch\examples\ble_gatt\app.overlay:30 */
					};
				};
			};
		};

		/* node '/soc/ppi@4001f000' defined in zephyr\dts\arm\nordic\nrf52840.dtsi:433 */
		ppi: ppi@4001f000 {
			compatible = "nordic,nrf-ppi"; /* in zephyr\dts\arm\nordic\nrf52840.dtsi:434 */
			reg = < 0x4001f000 0x1000 >;   /* in zephyr\dts\arm\nordic\nrf52840.dtsi:435 */
			status = "okay";               /* in zephyr\dts\arm\nordic\nrf52840.dtsi:436 */
		};

		/* node '/soc/mwu@40020000' defined in zephyr\dts\arm\nordic\nrf52840.dtsi:439 */
		mwu: mwu@40020000 {
			compatible = "nordic,nrf-mwu"; /* in zephyr\dts\arm\nordic\nrf52840.dtsi:440 */
			reg = < 0x40020000 0x1000 >;   /* in zephyr\dts\arm\nordic\nrf52840.dtsi:441 */
			status = "okay";               /* in zephyr\dts\arm\nordic\nrf52840.dtsi:442 */
		};

		/* node '/soc/pwm@40021000' defined in zephyr\dts\arm\nordic\nrf52840.dtsi:445 */
		pwm1: pwm@40021000 {
			compatible = "nordic,nrf-pwm"; /* in zephyr\dts\arm\nordic\nrf52840.dtsi:446 */
			reg = < 0x40021000 0x1000 >;   /* in zephyr\dts\arm\nordic\nrf52840.dtsi:447 */
			interrupts = < 0x21 0x1 >;     /* in zephyr\dts\arm\nordic\nrf52840.dtsi:448 */
			status = "disabled";           /* in zephyr\dts\arm\nordic\nrf52840.dtsi:449 */
			#pwm-cells = < 0x3 >;          /* in zephyr\dts\arm\nordic\nrf52840.dtsi:450 */
		};

		/* node '/soc/pwm@40022000' defined in zephyr\dts\arm\nordic\nrf52840.dtsi:453 */
		pwm2: pwm@40022000 {
			compatible = "nordic,nrf-pwm"; /* in zephyr\dts\arm\nordic\nrf52840.dtsi:454 */
			reg = < 0x40022000 0x1000 >;   /* in zephyr\dts\arm\nordic\nrf52840.dtsi:455 */
			interrupts = < 0x22 0x1 >;     /* in zephyr\dts\arm\nordic\nrf52840.dtsi:456 */
			status = "disabled";           /* in zephyr\dts\arm\nordic\nrf52840.dtsi:457 */
			#pwm-cells = < 0x3 >;          /* in zephyr\dts\arm\nordic\nrf52840.dtsi:458 */
		};

		/* node '/soc/spi@40023000' defined in zephyr\dts\arm\nordic\nrf52840.dtsi:461 */
		spi2: xiao_spi: spi@40023000 {
			compatible = "nordic,nrf-spi";  /* in zephyr\boards\seeed\xiao_ble\xiao_ble_common.dtsi:107 */
			#address-cells = < 0x1 >;       /* in zephyr\dts\arm\nordic\nrf52840.dtsi:470 */
			#size-cells = < 0x0 >;          /* in zephyr\dts\arm\nordic\nrf52840.dtsi:471 */
			reg = < 0x40023000 0x1000 >;    /* in zephyr\dts\arm\nordic\nrf52840.dtsi:472 */
			interrupts = < 0x23 0x1 >;      /* in zephyr\dts\arm\nordic\nrf52840.dtsi:473 */
			max-frequency = < 0x7a1200 >;   /* in zephyr\dts\arm\nordic\nrf52840.dtsi:474 */
			easydma-maxcnt-bits = < 0x10 >; /* in zephyr\dts\arm\nordic\nrf52840.dtsi:475 */
			status = "okay";                /* in zephyr\boards\seeed\xiao_ble\xiao_ble_common.dtsi:108 */
			pinctrl-0 = < &spi2_default >;  /* in zephyr\boards\seeed\xiao_ble\xiao_ble_common.dtsi:109 */
			pinctrl-1 = < &spi2_sleep >;    /* in zephyr\boards\seeed\xiao_ble\xiao_ble_common.dtsi:110 */
			pinctrl-names = "default",
			                "sleep";        /* in zephyr\boards\seeed\xiao_ble\xiao_ble_common.dtsi:111 */
		};

		/* node '/soc/rtc@40024000' defined in zephyr\dts\arm\nordic\nrf52840.dtsi:479 */
		rtc2: rtc@40024000 {
			compatible = "nordic,nrf-rtc"; /* in zephyr\dts\arm\nordic\nrf52840.dtsi:480 */
			reg = < 0x40024000 0x1000 >;   /* in zephyr\dts\arm\nordic\nrf52840.dtsi:481 */
			cc-num = < 0x4 >;              /* in zephyr\dts\arm\nordic\nrf52840.dtsi:482 */
			interrupts = < 0x24 0x1 >;     /* in zephyr\dts\arm\nordic\nrf52840.dtsi:483 */
			status = "disabled";           /* in zephyr\dts\arm\nordic\nrf52840.dtsi:484 */
			clock-frequency = < 0x8000 >;  /* in zephyr\dts\arm\nordic\nrf52840.dtsi:485 */
			prescaler = < 0x1 >;           /* in zephyr\dts\arm\nordic\nrf52840.dtsi:486 */
		};

		/* node '/soc/i2s@40025000' defined in zephyr\dts\arm\nordic\nrf52840.dtsi:489 */
		i2s0: i2s@40025000 {
			compatible = "nordic,nrf-i2s"; /* in zephyr\dts\arm\nordic\nrf52840.dtsi:490 */
			#address-cells = < 0x1 >;      /* in zephyr\dts\arm\nordic\nrf52840.dtsi:491 */
			#size-cells = < 0x0 >;         /* in zephyr\dts\arm\nordic\nrf52840.dtsi:492 */
			reg = < 0x40025000 0x1000 >;   /* in zephyr\dts\arm\nordic\nrf52840.dtsi:493 */
			interrupts = < 0x25 0x1 >;     /* in zephyr\dts\arm\nordic\nrf52840.dtsi:494 */
			status = "disabled";           /* in zephyr\dts\arm\nordic\nrf52840.dtsi:495 */
		};

		/* node '/soc/usbd@40027000' defined in zephyr\dts\arm\nordic\nrf52840.dtsi:498 */
		usbd: zephyr_udc0: usbd@40027000 {
			compatible = "nordic,nrf-usbd"; /* in zephyr\boards\seeed\xiao_ble\xiao_ble_common.dtsi:142 */
			reg = < 0x40027000 0x1000 >;    /* in zephyr\dts\arm\nordic\nrf52840.dtsi:500 */
			interrupts = < 0x27 0x1 >;      /* in zephyr\dts\arm\nordic\nrf52840.dtsi:501 */
			num-bidir-endpoints = < 0x1 >;  /* in zephyr\dts\arm\nordic\nrf52840.dtsi:502 */
			num-in-endpoints = < 0x7 >;     /* in zephyr\dts\arm\nordic\nrf52840.dtsi:503 */
			num-out-endpoints = < 0x7 >;    /* in zephyr\dts\arm\nordic\nrf52840.dtsi:504 */
			num-isoin-endpoints = < 0x1 >;  /* in zephyr\dts\arm\nordic\nrf52840.dtsi:505 */
			num-isoout-endpoints = < 0x1 >; /* in zephyr\dts\arm\nordic\nrf52840.dtsi:506 */
			status = "okay";                /* in zephyr\boards\seeed\xiao_ble\xiao_ble_common.dtsi:143 */

			/* node '/soc/usbd@40027000/board_cdc_acm_uart' defined in zephyr\boards\common\usb\cdc_acm_serial.dtsi:18 */
			board_cdc_acm_uart: board_cdc_acm_uart {
				compatible = "zephyr,cdc-acm-uart"; /* in zephyr\boards\common\usb\cdc_acm_serial.dtsi:19 */
			};
		};

		/* node '/soc/uart@40028000' defined in zephyr\dts\arm\nordic\nrf52840.dtsi:510 */
		uart1: uart@40028000 {
			compatible = "nordic,nrf-uarte"; /* in zephyr\dts\arm\nordic\nrf52840.dtsi:511 */
			reg = < 0x40028000 0x1000 >;     /* in zephyr\dts\arm\nordic\nrf52840.dtsi:512 */
			interrupts = < 0x28 0x1 >;       /* in zephyr\dts\arm\nordic\nrf52840.dtsi:513 */
			status = "disabled";             /* in zephyr\dts\arm\nordic\nrf52840.dtsi:514 */
		};

		/* node '/soc/qspi@40029000' defined in zephyr\dts\arm\nordic\nrf52840.dtsi:517 */
		qspi: qspi@40029000 {
			compatible = "nordic,nrf-qspi"; /* in zephyr\dts\arm\nordic\nrf52840.dtsi:518 */
			#address-cells = < 0x1 >;       /* in zephyr\dts\arm\nordic\nrf52840.dtsi:519 */
			#size-cells = < 0x0 >;          /* in zephyr\dts\arm\nordic\nrf52840.dtsi:520 */
			reg = < 0x40029000 0x1000 >,
			      < 0x12000000 0x8000000 >; /* in zephyr\dts\arm\nordic\nrf52840.dtsi:521 */
			reg-names = "qspi",
			            "qspi_mm";          /* in zephyr\dts\arm\nordic\nrf52840.dtsi:522 */
			interrupts = < 0x29 0x1 >;      /* in zephyr\dts\arm\nordic\nrf52840.dtsi:523 */
			status = "okay";                /* in zephyr\boards\seeed\xiao_ble\xiao_ble_common.dtsi:115 */
			pinctrl-0 = < &qspi_default >;  /* in zephyr\boards\seeed\xiao_ble\xiao_ble_common.dtsi:116 */
			pinctrl-1 = < &qspi_sleep >;    /* in zephyr\boards\seeed\xiao_ble\xiao_ble_common.dtsi:117 */
			pinctrl-names = "default",
			                "sleep";        /* in zephyr\boards\seeed\xiao_ble\xiao_ble_common.dtsi:118 */

			/* node '/soc/qspi@40029000/p25q16h@0' defined in zephyr\boards\seeed\xiao_ble\xiao_ble_common.dtsi:119 */
			p25q16h: p25q16h@0 {
				compatible = "nordic,qspi-nor";                                                                                             /* in zephyr\boards\seeed\xiao_ble\xiao_ble_common.dtsi:120 */
				reg = < 0x0 >;                                                                                                              /* in zephyr\boards\seeed\xiao_ble\xiao_ble_common.dtsi:121 */
				sck-frequency = < 0x632ea00 >;                                                                                              /* in zephyr\boards\seeed\xiao_ble\xiao_ble_common.dtsi:122 */
				quad-enable-requirements = "S2B1v1";                                                                                        /* in zephyr\boards\seeed\xiao_ble\xiao_ble_common.dtsi:123 */
				jedec-id = [ 85 60 15 ];                                                                                                    /* in zephyr\boards\seeed\xiao_ble\xiao_ble_common.dtsi:124 */
				sfdp-bfp = [ E5 20 F1 FF FF FF FF 00 44 EB 08 6B 08 3B 80 BB EE FF FF FF FF FF 00 FF FF FF 00 FF 0C 20 0F 52 10 D8 08 81 ]; /* in zephyr\boards\seeed\xiao_ble\xiao_ble_common.dtsi:125 */
				size = < 0x1000000 >;                                                                                                       /* in zephyr\boards\seeed\xiao_ble\xiao_ble_common.dtsi:130 */
				has-dpd;                                                                                                                    /* in zephyr\boards\seeed\xiao_ble\xiao_ble_common.dtsi:131 */
				t-enter-dpd = < 0xbb8 >;                                                                                                    /* in zephyr\boards\seeed\xiao_ble\xiao_ble_common.dtsi:132 */
				t-exit-dpd = < 0x1f40 >;                                                                                                    /* in zephyr\boards\seeed\xiao_ble\xiao_ble_common.dtsi:133 */

				/* node '/soc/qspi@40029000/p25q16h@0/partitions' defined in pouch\examples\ble_gatt\app.overlay:36 */
				partitions {
					compatible = "fixed-partitions"; /* in pouch\examples\ble_gatt\app.overlay:37 */
					#address-cells = < 0x1 >;        /* in pouch\examples\ble_gatt\app.overlay:38 */
					#size-cells = < 0x1 >;           /* in pouch\examples\ble_gatt\app.overlay:39 */

					/* node '/soc/qspi@40029000/p25q16h@0/partitions/partition@0' defined in pouch\examples\ble_gatt\app.overlay:41 */
					slot1_partition: partition@0 {
						label = "slot1";       /* in pouch\examples\ble_gatt\app.overlay:42 */
						reg = < 0x0 0x61000 >; /* in pouch\examples\ble_gatt\app.overlay:43 */
					};
				};
			};
		};

		/* node '/soc/pwm@4002d000' defined in zephyr\dts\arm\nordic\nrf52840.dtsi:527 */
		pwm3: pwm@4002d000 {
			compatible = "nordic,nrf-pwm"; /* in zephyr\dts\arm\nordic\nrf52840.dtsi:528 */
			reg = < 0x4002d000 0x1000 >;   /* in zephyr\dts\arm\nordic\nrf52840.dtsi:529 */
			interrupts = < 0x2d 0x1 >;     /* in zephyr\dts\arm\nordic\nrf52840.dtsi:530 */
			status = "disabled";           /* in zephyr\dts\arm\nordic\nrf52840.dtsi:531 */
			#pwm-cells = < 0x3 >;          /* in zephyr\dts\arm\nordic\nrf52840.dtsi:532 */
		};

		/* node '/soc/spi@4002f000' defined in zephyr\dts\arm\nordic\nrf52840.dtsi:535 */
		spi3: spi@4002f000 {
			compatible = "nordic,nrf-spim"; /* in zephyr\dts\arm\nordic\nrf52840.dtsi:536 */
			#address-cells = < 0x1 >;       /* in zephyr\dts\arm\nordic\nrf52840.dtsi:537 */
			#size-cells = < 0x0 >;          /* in zephyr\dts\arm\nordic\nrf52840.dtsi:538 */
			reg = < 0x4002f000 0x1000 >;    /* in zephyr\dts\arm\nordic\nrf52840.dtsi:539 */
			interrupts = < 0x2f 0x1 >;      /* in zephyr\dts\arm\nordic\nrf52840.dtsi:540 */
			max-frequency = < 0x1e84800 >;  /* in zephyr\dts\arm\nordic\nrf52840.dtsi:541 */
			easydma-maxcnt-bits = < 0x10 >; /* in zephyr\dts\arm\nordic\nrf52840.dtsi:542 */
			rx-delay-supported;             /* in zephyr\dts\arm\nordic\nrf52840.dtsi:543 */
			rx-delay = < 0x2 >;             /* in zephyr\dts\arm\nordic\nrf52840.dtsi:544 */
			status = "disabled";            /* in zephyr\dts\arm\nordic\nrf52840.dtsi:545 */
		};

		/* node '/soc/gpio@50000000' defined in zephyr\dts\arm\nordic\nrf52840.dtsi:548 */
		gpio0: gpio@50000000 {
			compatible = "nordic,nrf-gpio";              /* in zephyr\dts\arm\nordic\nrf52840.dtsi:549 */
			gpio-controller;                             /* in zephyr\dts\arm\nordic\nrf52840.dtsi:550 */
			reg = < 0x50000000 0x200 0x50000500 0x300 >; /* in zephyr\dts\arm\nordic\nrf52840.dtsi:551 */
			#gpio-cells = < 0x2 >;                       /* in zephyr\dts\arm\nordic\nrf52840.dtsi:553 */
			status = "okay";                             /* in zephyr\boards\seeed\xiao_ble\xiao_ble_common.dtsi:74 */
			port = < 0x0 >;                              /* in zephyr\dts\arm\nordic\nrf52840.dtsi:555 */
			gpiote-instance = < &gpiote >;               /* in zephyr\dts\arm\nordic\nrf52840.dtsi:556 */
			phandle = < 0xe >;                           /* in zephyr\boards\seeed\xiao_ble\seeed_xiao_connector.dtsi:15 */
		};

		/* node '/soc/gpio@50000300' defined in zephyr\dts\arm\nordic\nrf52840.dtsi:559 */
		gpio1: gpio@50000300 {
			compatible = "nordic,nrf-gpio";              /* in zephyr\dts\arm\nordic\nrf52840.dtsi:560 */
			gpio-controller;                             /* in zephyr\dts\arm\nordic\nrf52840.dtsi:561 */
			reg = < 0x50000300 0x200 0x50000800 0x300 >; /* in zephyr\dts\arm\nordic\nrf52840.dtsi:562 */
			#gpio-cells = < 0x2 >;                       /* in zephyr\dts\arm\nordic\nrf52840.dtsi:564 */
			ngpios = < 0x10 >;                           /* in zephyr\dts\arm\nordic\nrf52840.dtsi:565 */
			status = "okay";                             /* in zephyr\boards\seeed\xiao_ble\xiao_ble_common.dtsi:78 */
			port = < 0x1 >;                              /* in zephyr\dts\arm\nordic\nrf52840.dtsi:567 */
			gpiote-instance = < &gpiote >;               /* in zephyr\dts\arm\nordic\nrf52840.dtsi:568 */
			phandle = < 0xf >;                           /* in zephyr\boards\seeed\xiao_ble\seeed_xiao_connector.dtsi:15 */
		};

		/* node '/soc/crypto@5002a000' defined in zephyr\dts\arm\nordic\nrf52840.dtsi:571 */
		cryptocell: crypto@5002a000 {
			compatible = "arm,cryptocell-310"; /* in zephyr\dts\arm\nordic\nrf52840.dtsi:572 */
			reg = < 0x5002a000 0x1000 >,
			      < 0x5002b000 0x1000 >;       /* in zephyr\dts\arm\nordic\nrf52840.dtsi:573 */
			reg-names = "wrapper",
			            "core";                /* in zephyr\dts\arm\nordic\nrf52840.dtsi:574 */
			interrupts = < 0x2a 0x1 >;         /* in zephyr\dts\arm\nordic\nrf52840.dtsi:575 */
			status = "okay";                   /* in zephyr\dts\arm\nordic\nrf52840.dtsi:576 */
		};
	};

	/* node '/pin-controller' defined in zephyr\dts\vendor\nordic\nrf_common.dtsi:25 */
	pinctrl: pin-controller {
		compatible = "nordic,nrf-pinctrl"; /* in zephyr\dts\vendor\nordic\nrf_common.dtsi:30 */

		/* node '/pin-controller/uart0_default' defined in zephyr\boards\seeed\xiao_ble\xiao_ble-pinctrl.dtsi:7 */
		uart0_default: uart0_default {
			phandle = < 0x2 >; /* in zephyr\boards\seeed\xiao_ble\xiao_ble_common.dtsi:85 */

			/* node '/pin-controller/uart0_default/group1' defined in zephyr\boards\seeed\xiao_ble\xiao_ble-pinctrl.dtsi:8 */
			group1 {
				psels = < 0x2b >; /* in zephyr\boards\seeed\xiao_ble\xiao_ble-pinctrl.dtsi:9 */
			};

			/* node '/pin-controller/uart0_default/group2' defined in zephyr\boards\seeed\xiao_ble\xiao_ble-pinctrl.dtsi:11 */
			group2 {
				psels = < 0x100002c >; /* in zephyr\boards\seeed\xiao_ble\xiao_ble-pinctrl.dtsi:12 */
				bias-pull-up;          /* in zephyr\boards\seeed\xiao_ble\xiao_ble-pinctrl.dtsi:13 */
			};
		};

		/* node '/pin-controller/uart0_sleep' defined in zephyr\boards\seeed\xiao_ble\xiao_ble-pinctrl.dtsi:17 */
		uart0_sleep: uart0_sleep {
			phandle = < 0x3 >; /* in zephyr\boards\seeed\xiao_ble\xiao_ble_common.dtsi:86 */

			/* node '/pin-controller/uart0_sleep/group1' defined in zephyr\boards\seeed\xiao_ble\xiao_ble-pinctrl.dtsi:18 */
			group1 {
				psels = < 0x2b >,
				        < 0x100002c >; /* in zephyr\boards\seeed\xiao_ble\xiao_ble-pinctrl.dtsi:19 */
				low-power-enable;      /* in zephyr\boards\seeed\xiao_ble\xiao_ble-pinctrl.dtsi:21 */
			};
		};

		/* node '/pin-controller/i2c0_default' defined in zephyr\boards\seeed\xiao_ble\xiao_ble-pinctrl.dtsi:25 */
		i2c0_default: i2c0_default {

			/* node '/pin-controller/i2c0_default/group1' defined in zephyr\boards\seeed\xiao_ble\xiao_ble-pinctrl.dtsi:26 */
			group1 {
				psels = < 0xc000007 >,
				        < 0xb00001b >; /* in zephyr\boards\seeed\xiao_ble\xiao_ble-pinctrl.dtsi:27 */
			};
		};

		/* node '/pin-controller/i2c0_sleep' defined in zephyr\boards\seeed\xiao_ble\xiao_ble-pinctrl.dtsi:32 */
		i2c0_sleep: i2c0_sleep {

			/* node '/pin-controller/i2c0_sleep/group1' defined in zephyr\boards\seeed\xiao_ble\xiao_ble-pinctrl.dtsi:33 */
			group1 {
				psels = < 0xc000007 >,
				        < 0xb00001b >; /* in zephyr\boards\seeed\xiao_ble\xiao_ble-pinctrl.dtsi:34 */
				low-power-enable;      /* in zephyr\boards\seeed\xiao_ble\xiao_ble-pinctrl.dtsi:36 */
			};
		};

		/* node '/pin-controller/i2c1_default' defined in zephyr\boards\seeed\xiao_ble\xiao_ble-pinctrl.dtsi:40 */
		i2c1_default: i2c1_default {
			phandle = < 0x4 >; /* in zephyr\boards\seeed\xiao_ble\xiao_ble_common.dtsi:94 */

			/* node '/pin-controller/i2c1_default/group1' defined in zephyr\boards\seeed\xiao_ble\xiao_ble-pinctrl.dtsi:41 */
			group1 {
				psels = < 0xc000004 >,
				        < 0xb000005 >; /* in zephyr\boards\seeed\xiao_ble\xiao_ble-pinctrl.dtsi:42 */
			};
		};

		/* node '/pin-controller/i2c1_sleep' defined in zephyr\boards\seeed\xiao_ble\xiao_ble-pinctrl.dtsi:47 */
		i2c1_sleep: i2c1_sleep {
			phandle = < 0x5 >; /* in zephyr\boards\seeed\xiao_ble\xiao_ble_common.dtsi:95 */

			/* node '/pin-controller/i2c1_sleep/group1' defined in zephyr\boards\seeed\xiao_ble\xiao_ble-pinctrl.dtsi:48 */
			group1 {
				psels = < 0xc000004 >,
				        < 0xb000005 >; /* in zephyr\boards\seeed\xiao_ble\xiao_ble-pinctrl.dtsi:49 */
				low-power-enable;      /* in zephyr\boards\seeed\xiao_ble\xiao_ble-pinctrl.dtsi:51 */
			};
		};

		/* node '/pin-controller/pdm0_default' defined in zephyr\boards\seeed\xiao_ble\xiao_ble-pinctrl.dtsi:55 */
		pdm0_default: pdm0_default {

			/* node '/pin-controller/pdm0_default/group1' defined in zephyr\boards\seeed\xiao_ble\xiao_ble-pinctrl.dtsi:56 */
			group1 {
				psels = < 0x14000020 >,
				        < 0x15000010 >; /* in zephyr\boards\seeed\xiao_ble\xiao_ble-pinctrl.dtsi:57 */
			};
		};

		/* node '/pin-controller/pdm0_sleep' defined in zephyr\boards\seeed\xiao_ble\xiao_ble-pinctrl.dtsi:62 */
		pdm0_sleep: pdm0_sleep {

			/* node '/pin-controller/pdm0_sleep/group1' defined in zephyr\boards\seeed\xiao_ble\xiao_ble-pinctrl.dtsi:63 */
			group1 {
				psels = < 0x14000020 >,
				        < 0x15000010 >; /* in zephyr\boards\seeed\xiao_ble\xiao_ble-pinctrl.dtsi:64 */
				low-power-enable;       /* in zephyr\boards\seeed\xiao_ble\xiao_ble-pinctrl.dtsi:66 */
			};
		};

		/* node '/pin-controller/pwm0_default' defined in zephyr\boards\seeed\xiao_ble\xiao_ble-pinctrl.dtsi:70 */
		pwm0_default: pwm0_default {
			phandle = < 0x6 >; /* in zephyr\boards\seeed\xiao_ble\xiao_ble_common.dtsi:101 */

			/* node '/pin-controller/pwm0_default/group1' defined in zephyr\boards\seeed\xiao_ble\xiao_ble-pinctrl.dtsi:71 */
			group1 {
				psels = < 0x16000011 >; /* in zephyr\boards\seeed\xiao_ble\xiao_ble-pinctrl.dtsi:72 */
				nordic,invert;          /* in zephyr\boards\seeed\xiao_ble\xiao_ble-pinctrl.dtsi:73 */
			};
		};

		/* node '/pin-controller/pwm0_sleep' defined in zephyr\boards\seeed\xiao_ble\xiao_ble-pinctrl.dtsi:77 */
		pwm0_sleep: pwm0_sleep {
			phandle = < 0x7 >; /* in zephyr\boards\seeed\xiao_ble\xiao_ble_common.dtsi:102 */

			/* node '/pin-controller/pwm0_sleep/group1' defined in zephyr\boards\seeed\xiao_ble\xiao_ble-pinctrl.dtsi:78 */
			group1 {
				psels = < 0x16000011 >; /* in zephyr\boards\seeed\xiao_ble\xiao_ble-pinctrl.dtsi:79 */
				low-power-enable;       /* in zephyr\boards\seeed\xiao_ble\xiao_ble-pinctrl.dtsi:80 */
			};
		};

		/* node '/pin-controller/spi2_default' defined in zephyr\boards\seeed\xiao_ble\xiao_ble-pinctrl.dtsi:84 */
		spi2_default: spi2_default {
			phandle = < 0x8 >; /* in zephyr\boards\seeed\xiao_ble\xiao_ble_common.dtsi:109 */

			/* node '/pin-controller/spi2_default/group1' defined in zephyr\boards\seeed\xiao_ble\xiao_ble-pinctrl.dtsi:85 */
			group1 {
				psels = < 0x400002d >,
				        < 0x500002f >,
				        < 0x600002e >; /* in zephyr\boards\seeed\xiao_ble\xiao_ble-pinctrl.dtsi:86 */
			};
		};

		/* node '/pin-controller/spi2_sleep' defined in zephyr\boards\seeed\xiao_ble\xiao_ble-pinctrl.dtsi:92 */
		spi2_sleep: spi2_sleep {
			phandle = < 0x9 >; /* in zephyr\boards\seeed\xiao_ble\xiao_ble_common.dtsi:110 */

			/* node '/pin-controller/spi2_sleep/group1' defined in zephyr\boards\seeed\xiao_ble\xiao_ble-pinctrl.dtsi:93 */
			group1 {
				psels = < 0x400002d >,
				        < 0x500002f >,
				        < 0x600002e >; /* in zephyr\boards\seeed\xiao_ble\xiao_ble-pinctrl.dtsi:94 */
				low-power-enable;      /* in zephyr\boards\seeed\xiao_ble\xiao_ble-pinctrl.dtsi:97 */
			};
		};

		/* node '/pin-controller/spi3_default' defined in zephyr\boards\seeed\xiao_ble\xiao_ble-pinctrl.dtsi:101 */
		spi3_default: spi3_default {

			/* node '/pin-controller/spi3_default/group1' defined in zephyr\boards\seeed\xiao_ble\xiao_ble-pinctrl.dtsi:102 */
			group1 {
				psels = < 0x4000015 >,
				        < 0x5000014 >,
				        < 0x6000018 >; /* in zephyr\boards\seeed\xiao_ble\xiao_ble-pinctrl.dtsi:103 */
			};
		};

		/* node '/pin-controller/spi3_sleep' defined in zephyr\boards\seeed\xiao_ble\xiao_ble-pinctrl.dtsi:109 */
		spi3_sleep: spi3_sleep {

			/* node '/pin-controller/spi3_sleep/group1' defined in zephyr\boards\seeed\xiao_ble\xiao_ble-pinctrl.dtsi:110 */
			group1 {
				psels = < 0x4000015 >,
				        < 0x5000014 >,
				        < 0x6000018 >; /* in zephyr\boards\seeed\xiao_ble\xiao_ble-pinctrl.dtsi:111 */
				low-power-enable;      /* in zephyr\boards\seeed\xiao_ble\xiao_ble-pinctrl.dtsi:114 */
			};
		};

		/* node '/pin-controller/qspi_default' defined in zephyr\boards\seeed\xiao_ble\xiao_ble-pinctrl.dtsi:118 */
		qspi_default: qspi_default {
			phandle = < 0xa >; /* in zephyr\boards\seeed\xiao_ble\xiao_ble_common.dtsi:116 */

			/* node '/pin-controller/qspi_default/group1' defined in zephyr\boards\seeed\xiao_ble\xiao_ble-pinctrl.dtsi:119 */
			group1 {
				psels = < 0x1d000015 >,
				        < 0x1f000014 >,
				        < 0x20000018 >,
				        < 0x21000016 >,
				        < 0x22000017 >,
				        < 0x1e000019 >; /* in zephyr\boards\seeed\xiao_ble\xiao_ble-pinctrl.dtsi:120 */
			};
		};

		/* node '/pin-controller/qspi_sleep' defined in zephyr\boards\seeed\xiao_ble\xiao_ble-pinctrl.dtsi:129 */
		qspi_sleep: qspi_sleep {
			phandle = < 0xb >; /* in zephyr\boards\seeed\xiao_ble\xiao_ble_common.dtsi:117 */

			/* node '/pin-controller/qspi_sleep/group1' defined in zephyr\boards\seeed\xiao_ble\xiao_ble-pinctrl.dtsi:130 */
			group1 {
				psels = < 0x1d000015 >,
				        < 0x1f000014 >,
				        < 0x20000018 >,
				        < 0x21000016 >,
				        < 0x22000017 >; /* in zephyr\boards\seeed\xiao_ble\xiao_ble-pinctrl.dtsi:131 */
				low-power-enable;       /* in zephyr\boards\seeed\xiao_ble\xiao_ble-pinctrl.dtsi:136 */
			};

			/* node '/pin-controller/qspi_sleep/group2' defined in zephyr\boards\seeed\xiao_ble\xiao_ble-pinctrl.dtsi:138 */
			group2 {
				psels = < 0x1e000019 >; /* in zephyr\boards\seeed\xiao_ble\xiao_ble-pinctrl.dtsi:139 */
				low-power-enable;       /* in zephyr\boards\seeed\xiao_ble\xiao_ble-pinctrl.dtsi:140 */
				bias-pull-up;           /* in zephyr\boards\seeed\xiao_ble\xiao_ble-pinctrl.dtsi:141 */
			};
		};
	};

	/* node '/entropy_bt_hci' defined in zephyr\dts\vendor\nordic\nrf_common.dtsi:33 */
	rng_hci: entropy_bt_hci {
		compatible = "zephyr,bt-hci-entropy"; /* in zephyr\dts\vendor\nordic\nrf_common.dtsi:34 */
		status = "okay";                      /* in zephyr\dts\vendor\nordic\nrf_common.dtsi:35 */
	};

	/* node '/sw-pwm' defined in zephyr\dts\vendor\nordic\nrf_common.dtsi:38 */
	sw_pwm: sw-pwm {
		compatible = "nordic,nrf-sw-pwm"; /* in zephyr\dts\vendor\nordic\nrf_common.dtsi:39 */
		status = "disabled";              /* in zephyr\dts\vendor\nordic\nrf_common.dtsi:40 */
		generator = < &timer1 >;          /* in zephyr\dts\vendor\nordic\nrf_common.dtsi:41 */
		clock-prescaler = < 0x0 >;        /* in zephyr\dts\vendor\nordic\nrf_common.dtsi:42 */
		#pwm-cells = < 0x3 >;             /* in zephyr\dts\vendor\nordic\nrf_common.dtsi:43 */
	};

	/* node '/cpus' defined in zephyr\dts\arm\nordic\nrf52840.dtsi:15 */
	cpus {
		#address-cells = < 0x1 >; /* in zephyr\dts\arm\nordic\nrf52840.dtsi:16 */
		#size-cells = < 0x0 >;    /* in zephyr\dts\arm\nordic\nrf52840.dtsi:17 */

		/* node '/cpus/cpu@0' defined in zephyr\dts\arm\nordic\nrf52840.dtsi:19 */
		cpu@0 {
			device_type = "cpu";           /* in zephyr\dts\arm\nordic\nrf52840.dtsi:20 */
			compatible = "arm,cortex-m4f"; /* in zephyr\dts\arm\nordic\nrf52840.dtsi:21 */
			reg = < 0x0 >;                 /* in zephyr\dts\arm\nordic\nrf52840.dtsi:22 */
			#address-cells = < 0x1 >;      /* in zephyr\dts\arm\nordic\nrf52840.dtsi:23 */
			#size-cells = < 0x1 >;         /* in zephyr\dts\arm\nordic\nrf52840.dtsi:24 */

			/* node '/cpus/cpu@0/itm@e0000000' defined in zephyr\dts\arm\nordic\nrf52840.dtsi:26 */
			itm: itm@e0000000 {
				compatible = "arm,armv7m-itm";     /* in zephyr\dts\arm\nordic\nrf52840.dtsi:27 */
				reg = < 0xe0000000 0x1000 >;       /* in zephyr\dts\arm\nordic\nrf52840.dtsi:28 */
				swo-ref-frequency = < 0x1e84800 >; /* in zephyr\dts\arm\nordic\nrf52840.dtsi:29 */
			};
		};
	};

	/* node '/clocks' defined in zephyr\dts\arm\nordic\nrf52840.dtsi:34 */
	clocks {

		/* node '/clocks/hfxo' defined in zephyr\dts\arm\nordic\nrf52840.dtsi:35 */
		hfxo: hfxo {
			compatible = "nordic,nrf52-hfxo"; /* in zephyr\dts\arm\nordic\nrf52840.dtsi:36 */
			clock-frequency = < 0x3d09000 >;  /* in zephyr\dts\arm\nordic\nrf52840.dtsi:37 */
			startup-time-us = < 0x578 >;      /* in zephyr\dts\arm\nordic\nrf52840.dtsi:38 */
			#clock-cells = < 0x0 >;           /* in zephyr\dts\arm\nordic\nrf52840.dtsi:39 */
		};
	};

	/* node '/connector' defined in zephyr\boards\seeed\xiao_ble\seeed_xiao_connector.dtsi:9 */
	xiao_d: connector {
		compatible = "seeed,xiao-gpio";            /* in zephyr\boards\seeed\xiao_ble\seeed_xiao_connector.dtsi:10 */
		#gpio-cells = < 0x2 >;                     /* in zephyr\boards\seeed\xiao_ble\seeed_xiao_connector.dtsi:11 */
		gpio-map-mask = < 0xffffffff 0xffffffc0 >; /* in zephyr\boards\seeed\xiao_ble\seeed_xiao_connector.dtsi:12 */
		gpio-map-pass-thru = < 0x0 0x3f >;         /* in zephyr\boards\seeed\xiao_ble\seeed_xiao_connector.dtsi:13 */
		gpio-map = < 0x0 0x0 &gpio0 0x2 0x0 >,
		           < 0x1 0x0 &gpio0 0x3 0x0 >,
		           < 0x2 0x0 &gpio0 0x1c 0x0 >,
		           < 0x3 0x0 &gpio0 0x1d 0x0 >,
		           < 0x4 0x0 &gpio0 0x4 0x0 >,
		           < 0x5 0x0 &gpio0 0x5 0x0 >,
		           < 0x6 0x0 &gpio1 0xb 0x0 >,
		           < 0x7 0x0 &gpio1 0xc 0x0 >,
		           < 0x8 0x0 &gpio1 0xd 0x0 >,
		           < 0x9 0x0 &gpio1 0xe 0x0 >,
		           < 0xa 0x0 &gpio1 0xf 0x0 >;     /* in zephyr\boards\seeed\xiao_ble\seeed_xiao_connector.dtsi:15 */
	};

	/* node '/leds' defined in zephyr\boards\seeed\xiao_ble\xiao_ble_common.dtsi:18 */
	leds {
		compatible = "gpio-leds"; /* in zephyr\boards\seeed\xiao_ble\xiao_ble_common.dtsi:19 */

		/* node '/leds/led_0' defined in zephyr\boards\seeed\xiao_ble\xiao_ble_common.dtsi:20 */
		led0: led_0 {
			gpios = < &gpio0 0x1a 0x1 >; /* in zephyr\boards\seeed\xiao_ble\xiao_ble_common.dtsi:21 */
			label = "Red LED";           /* in zephyr\boards\seeed\xiao_ble\xiao_ble_common.dtsi:22 */
		};

		/* node '/leds/led_1' defined in zephyr\boards\seeed\xiao_ble\xiao_ble_common.dtsi:24 */
		led1: led_1 {
			gpios = < &gpio0 0x1e 0x1 >; /* in zephyr\boards\seeed\xiao_ble\xiao_ble_common.dtsi:25 */
			label = "Green LED";         /* in zephyr\boards\seeed\xiao_ble\xiao_ble_common.dtsi:26 */
		};

		/* node '/leds/led_2' defined in zephyr\boards\seeed\xiao_ble\xiao_ble_common.dtsi:28 */
		led2: led_2 {
			gpios = < &gpio0 0x6 0x1 >; /* in zephyr\boards\seeed\xiao_ble\xiao_ble_common.dtsi:29 */
			label = "Blue LED";         /* in zephyr\boards\seeed\xiao_ble\xiao_ble_common.dtsi:30 */
		};
	};

	/* node '/pwmleds' defined in zephyr\boards\seeed\xiao_ble\xiao_ble_common.dtsi:34 */
	pwmleds {
		compatible = "pwm-leds"; /* in zephyr\boards\seeed\xiao_ble\xiao_ble_common.dtsi:35 */

		/* node '/pwmleds/pwm_led_0' defined in zephyr\boards\seeed\xiao_ble\xiao_ble_common.dtsi:36 */
		pwm_led0: pwm_led_0 {
			pwms = < &pwm0 0x0 0x1312d00 0x1 >; /* in zephyr\boards\seeed\xiao_ble\xiao_ble_common.dtsi:37 */
		};
	};

	/* node '/fstab' defined in pouch\examples\ble_gatt\app.overlay:10 */
	fstab {
		compatible = "zephyr,fstab"; /* in pouch\examples\ble_gatt\app.overlay:11 */

		/* node '/fstab/lfs1' defined in pouch\examples\ble_gatt\app.overlay:12 */
		lfs1: lfs1 {
			compatible = "zephyr,fstab,littlefs"; /* in pouch\examples\ble_gatt\app.overlay:13 */
			mount-point = "/lfs1";                /* in pouch\examples\ble_gatt\app.overlay:14 */
			partition = < &storage_partition >;   /* in pouch\examples\ble_gatt\app.overlay:15 */
			automount;                            /* in pouch\examples\ble_gatt\app.overlay:16 */
			read-size = < 0x10 >;                 /* in pouch\examples\ble_gatt\app.overlay:17 */
			prog-size = < 0x10 >;                 /* in pouch\examples\ble_gatt\app.overlay:18 */
			cache-size = < 0x40 >;                /* in pouch\examples\ble_gatt\app.overlay:19 */
			lookahead-size = < 0x20 >;            /* in pouch\examples\ble_gatt\app.overlay:20 */
			block-cycles = < 0x200 >;             /* in pouch\examples\ble_gatt\app.overlay:21 */
		};
	};
};
